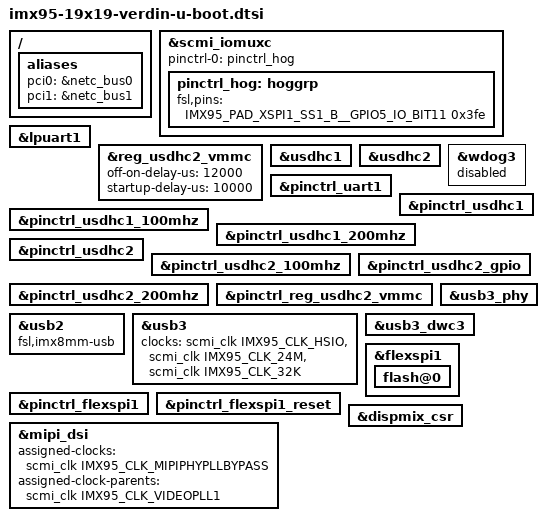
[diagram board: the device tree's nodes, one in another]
// SPDX-License-Identifier: GPL-2.0+
/*
 * Copyright 2023-2025 NXP
 */

/ {
	aliases {
		pci0 = &netc_bus0;
		pci1 = &netc_bus1;
	};
};

&scmi_iomuxc {
	pinctrl-names = "default";
	pinctrl-0 = <&pinctrl_hog>;

	pinctrl_hog: hoggrp {
		bootph-pre-ram;

		fsl,pins = <
			IMX95_PAD_XSPI1_SS1_B__GPIO5_IO_BIT11			0x3fe
		>;
	};
};

&lpuart1 {
	bootph-pre-ram;
};

&reg_usdhc2_vmmc {
	bootph-pre-ram;
	off-on-delay-us = <12000>;
	startup-delay-us = <10000>;
};

&usdhc1 {
	bootph-pre-ram;
};

&usdhc2 {
	bootph-pre-ram;
};

&wdog3 {
	status = "disabled";
};

&pinctrl_uart1 {
	bootph-pre-ram;
};

&pinctrl_usdhc1 {
	bootph-pre-ram;
};

&pinctrl_usdhc1_100mhz {
	bootph-pre-ram;
};

&pinctrl_usdhc1_200mhz {
	bootph-pre-ram;
};

&pinctrl_usdhc2 {
	bootph-pre-ram;
};

&pinctrl_usdhc2_100mhz {
	bootph-pre-ram;
};

&pinctrl_usdhc2_200mhz {
	bootph-pre-ram;
};

&pinctrl_usdhc2_gpio {
	bootph-pre-ram;
};

&pinctrl_reg_usdhc2_vmmc {
	bootph-pre-ram;
};

&usb2 {
	compatible = "fsl,imx8mm-usb", "fsl,imx7d-usb";
	/delete-property/power-domains;
};

&usb3_phy {
	bootph-pre-ram;
};

&usb3 {
	clocks = <&scmi_clk IMX95_CLK_HSIO>,
			 <&scmi_clk IMX95_CLK_24M>,
			 <&scmi_clk IMX95_CLK_32K>;
	clock-names = "hsio", "ref", "suspend";

	/delete-property/power-domains;
	bootph-pre-ram;
};

&usb3_dwc3 {
	bootph-pre-ram;
};

&flexspi1 {
	bootph-pre-ram;

	flash@0{
		bootph-pre-ram;
	};
};

&pinctrl_flexspi1 {
	bootph-pre-ram;
};

&pinctrl_flexspi1_reset {
	bootph-pre-ram;
};

&dispmix_csr {
	/delete-property/ assigned-clocks;
	/delete-property/ assigned-clock-rates;
	/delete-property/ assigned-clock-parents;
};

&mipi_dsi {
	assigned-clocks = <&scmi_clk IMX95_CLK_MIPIPHYPLLBYPASS>;
	assigned-clock-parents = <&scmi_clk IMX95_CLK_VIDEOPLL1>;
};
